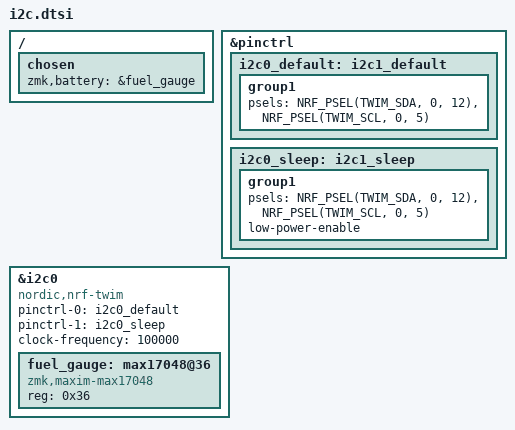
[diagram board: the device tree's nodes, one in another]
/*
 * copyright (c) 2025 ZMK project contributors
 *
 * SPDX-license-identifier: MIT
 */

/ {
    chosen {
        zmk,battery = &fuel_gauge;
    };
};

&pinctrl {
    i2c0_default: i2c1_default {
        group1 {
            psels = <NRF_PSEL(TWIM_SDA, 0, 12)>,
                    <NRF_PSEL(TWIM_SCL, 0, 5)>;
        };
    };

    i2c0_sleep: i2c1_sleep {
        group1 {
            psels = <NRF_PSEL(TWIM_SDA, 0, 12)>,
                    <NRF_PSEL(TWIM_SCL, 0, 5)>;
            low-power-enable;
        };
    };
};

&i2c0 {
    status = "okay";
    compatible = "nordic,nrf-twim";
    pinctrl-0 = <&i2c0_default>;
    pinctrl-1 = <&i2c0_sleep>;
    pinctrl-names = "default", "sleep";
    clock-frequency = <100000>;

    fuel_gauge: max17048@36 {
        compatible = "zmk,maxim-max17048";
		reg = <0x36>;
    };
};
